AUTOSAR XML (schema 00049)
package /Application/DltConfig
  dlt log channel to process mapping DltLogChannelToProcessMapping_OTAClient_TO_OTAClient: dlt-log-channel=OTAClient, process=OTAClient
package /Application/Executable
  executable OTAClient: category=PLATFORM_LEVEL, logging-behavior=USES-LOGGING, reporting-behavior=REPORTS-EXECUTION-STATE, version=1.0.0
    root sw component prototype AA: application-type=OTAClient
package /Application/Manifest
  service instance to port prototype mapping OTAClient_AA_PPortOtaMonitoring: port-prototype=AA.PPortOtaMonitoring, service-instance=EEVP_OTAClient_Provider_OtaMonitoring
  service instance to port prototype mapping OTAClient_AA_PPortOtaSubscription: port-prototype=AA.PPortOtaSubscription, service-instance=EEVP_OTAClient_Provider_OtaSubscription
  service instance to port prototype mapping OTAClient_AA_VehiclePackageManagement: port-prototype=AA.VehiclePackageManagement, service-instance=EEVP_OTAClient_Consumer_VehiclePackageManagement
package /Application/Process
  process OTAClient: executable=OTAClient, state-dependent-startup-config{execution-dependency=VUCM.Running, function-group-state=[MachineFG.Startup, MachineFG.Shutdown, MachineFG.Restart, MachineFG.Verify], resource-group=DefaultResourceGroup, startup-config=OTAClient}
    process state machine OTAClient: type=ProcessState
package /Application/StartupConfig
  startup config set EEVP_OTAClient_StartupConfig
    startup config OTAClient: scheduling-policy=SCHED_OTHER, scheduling-priority=0, timeout={enter-timeout-value=2.0, exit-timeout-value=2.0}
package /Application/SwComponent
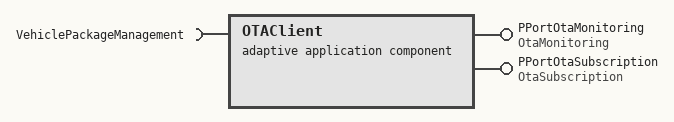
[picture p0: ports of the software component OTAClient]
  adaptive application sw component type OTAClient
    provide port PPortOtaMonitoring: provided-interface=OtaMonitoring
    provide port PPortOtaSubscription: provided-interface=OtaSubscription
    require port VehiclePackageManagement: required-interface=VehiclePackageManagement
